# iostr912fa register map
Registers are 32-bit, access not given, no defined reset value unless marked. A register's access mark holds for its fields unless they carry their own. Addresses are absolute; registers are grouped by the start of their names; [hi:lo] are bit positions; {n}, {i} and the like mark numbered series; 'fields as' and 'values as' point back to an identical list.

## I2C0
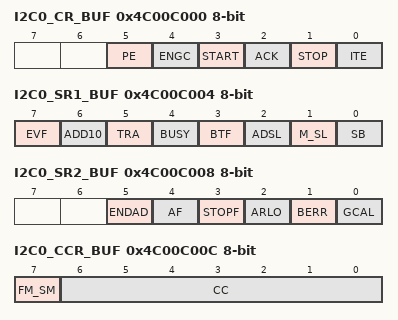
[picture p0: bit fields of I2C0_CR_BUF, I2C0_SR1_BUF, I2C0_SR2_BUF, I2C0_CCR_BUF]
0x4C00C000 I2C0_CR_BUF 8-bit
  [5] PE, [4] ENGC, [3] START, [2] ACK, [1] STOP, [0] ITE
0x4C00C004 I2C0_SR1_BUF 8-bit
  [7] EVF, [6] ADD10, [5] TRA, [4] BUSY, [3] BTF, [2] ADSL, [1] M_SL, [0] SB
0x4C00C008 I2C0_SR2_BUF 8-bit
  [5] ENDAD, [4] AF, [3] STOPF, [2] ARLO, [1] BERR, [0] GCAL
0x4C00C00C I2C0_CCR_BUF 8-bit
  [7] FM_SM, [6:0] CC
0x4C00C010 I2C0_OAR1_BUF 8-bit
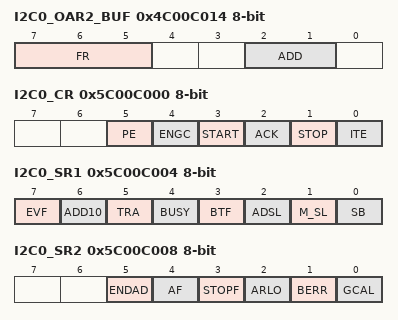
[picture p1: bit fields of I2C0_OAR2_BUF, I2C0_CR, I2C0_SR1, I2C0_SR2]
0x4C00C014 I2C0_OAR2_BUF 8-bit
  [7:5] FR, [2:1] ADD
0x4C00C018 I2C0_DR_BUF 8-bit
0x4C00C01C I2C0_ECCR_BUF 8-bit
  [4:0] CC
0x5C00C000 I2C0_CR 8-bit
  [5] PE, [4] ENGC, [3] START, [2] ACK, [1] STOP, [0] ITE
0x5C00C004 I2C0_SR1 8-bit
  fields as I2C0_SR1_BUF
0x5C00C008 I2C0_SR2 8-bit
  [5] ENDAD, [4] AF, [3] STOPF, [2] ARLO, [1] BERR, [0] GCAL
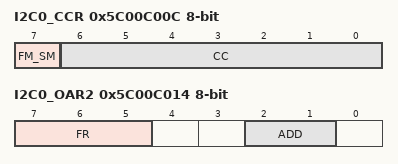
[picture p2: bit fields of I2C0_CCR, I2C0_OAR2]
0x5C00C00C I2C0_CCR 8-bit
  [7] FM_SM, [6:0] CC
0x5C00C010 I2C0_OAR1 8-bit
0x5C00C014 I2C0_OAR2 8-bit
  [7:5] FR, [2:1] ADD
0x5C00C018 I2C0_DR 8-bit
0x5C00C01C I2C0_ECCR 8-bit
  [4:0] CC

## I2C1
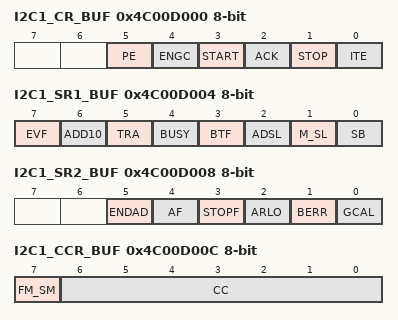
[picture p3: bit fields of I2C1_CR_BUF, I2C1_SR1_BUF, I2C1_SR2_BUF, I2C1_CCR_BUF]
0x4C00D000 I2C1_CR_BUF 8-bit
  [5] PE, [4] ENGC, [3] START, [2] ACK, [1] STOP, [0] ITE
0x4C00D004 I2C1_SR1_BUF 8-bit
  [7] EVF, [6] ADD10, [5] TRA, [4] BUSY, [3] BTF, [2] ADSL, [1] M_SL, [0] SB
0x4C00D008 I2C1_SR2_BUF 8-bit
  [5] ENDAD, [4] AF, [3] STOPF, [2] ARLO, [1] BERR, [0] GCAL
0x4C00D00C I2C1_CCR_BUF 8-bit
  [7] FM_SM, [6:0] CC
0x4C00D010 I2C1_OAR1_BUF 8-bit
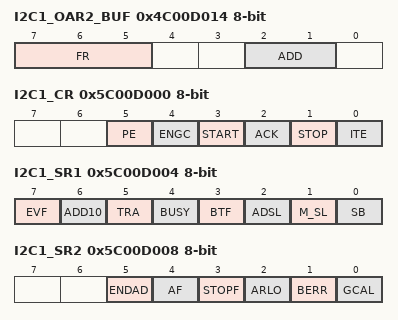
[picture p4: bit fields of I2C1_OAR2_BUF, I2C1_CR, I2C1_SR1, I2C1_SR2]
0x4C00D014 I2C1_OAR2_BUF 8-bit
  [7:5] FR, [2:1] ADD
0x4C00D018 I2C1_DR_BUF 8-bit
0x4C00D01C I2C1_ECCR_BUF 8-bit
  [4:0] CC
0x5C00D000 I2C1_CR 8-bit
  [5] PE, [4] ENGC, [3] START, [2] ACK, [1] STOP, [0] ITE
0x5C00D004 I2C1_SR1 8-bit
  fields as I2C1_SR1_BUF
0x5C00D008 I2C1_SR2 8-bit
  [5] ENDAD, [4] AF, [3] STOPF, [2] ARLO, [1] BERR, [0] GCAL
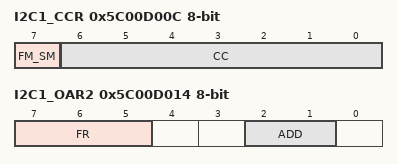
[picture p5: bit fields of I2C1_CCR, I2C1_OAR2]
0x5C00D00C I2C1_CCR 8-bit
  [7] FM_SM, [6:0] CC
0x5C00D010 I2C1_OAR1 8-bit
0x5C00D014 I2C1_OAR2 8-bit
  [7:5] FR, [2:1] ADD
0x5C00D018 I2C1_DR 8-bit
0x5C00D01C I2C1_ECCR 8-bit
  [4:0] CC

## MC
0x4C003000 MC_TCPT_BUF 16-bit
0x4C003004 MC_TCMP_BUF 8-bit
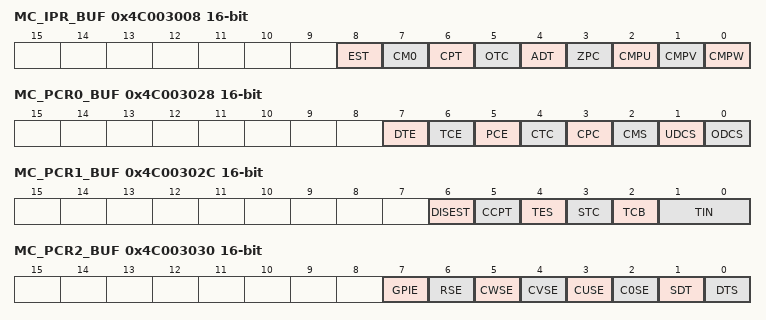
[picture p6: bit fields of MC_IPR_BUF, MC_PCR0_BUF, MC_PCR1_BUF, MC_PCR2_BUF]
0x4C003008 MC_IPR_BUF 16-bit
  [8] EST, [7] CM0, [6] CPT, [5] OTC, [4] ADT, [3] ZPC, [2] CMPU, [1] CMPV, [0] CMPW
0x4C00300C MC_TPRS_BUF 16-bit
  [11:0] TPRS
0x4C003010 MC_CPRS_BUF 8-bit
0x4C003014 MC_REP_BUF 8-bit
0x4C003018 MC_CMPW_BUF 16-bit
0x4C00301C MC_CMPV_BUF 16-bit
0x4C003020 MC_CMPU_BUF 16-bit
0x4C003024 MC_CMP0_BUF 16-bit
0x4C003028 MC_PCR0_BUF 16-bit
  [7] DTE, [6] TCE, [5] PCE, [4] CTC, [3] CPC, [2] CMS, [1] UDCS, [0] ODCS
0x4C00302C MC_PCR1_BUF 16-bit
  [6] DISEST, [5] CCPT, [4] TES, [3] STC, [2] TCB, [1:0] TIN
0x4C003030 MC_PCR2_BUF 16-bit
  [7] GPIE, [6] RSE, [5] CWSE, [4] CVSE, [3] CUSE, [2] C0SE, [1] SDT, [0] DTS
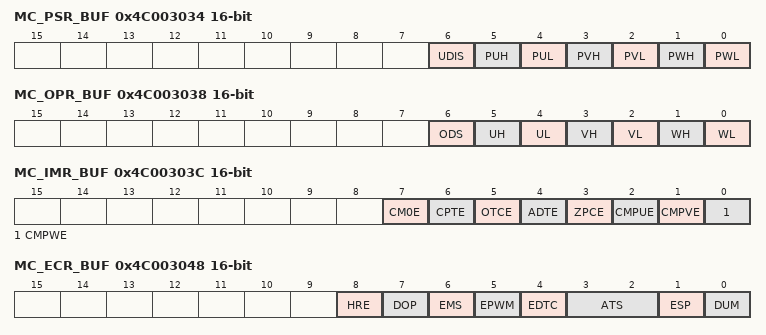
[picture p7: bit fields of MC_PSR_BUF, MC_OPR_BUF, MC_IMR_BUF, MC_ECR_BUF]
0x4C003034 MC_PSR_BUF 16-bit
  [6] UDIS, [5] PUH, [4] PUL, [3] PVH, [2] PVL, [1] PWH, [0] PWL
0x4C003038 MC_OPR_BUF 16-bit
  [6] ODS, [5] UH, [4] UL, [3] VH, [2] VL, [1] WH, [0] WL
0x4C00303C MC_IMR_BUF 16-bit
  [7] CM0E, [6] CPTE, [5] OTCE, [4] ADTE, [3] ZPCE, [2] CMPUE, [1] CMPVE, [0] CMPWE
0x4C003040 MC_DTG_BUF 16-bit
  [9:0] DTG
0x4C003044 MC_ESC_BUF 16-bit
0x4C003048 MC_ECR_BUF 16-bit
  [8] HRE, [7] DOP, [6] EMS, [5] EPWM, [4] EDTC, [3:2] ATS, [1] ESP, [0] DUM
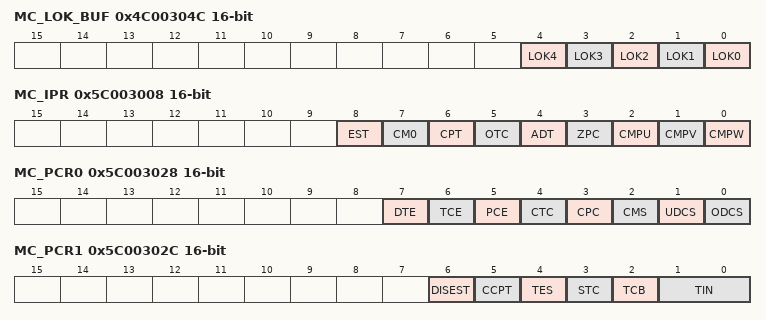
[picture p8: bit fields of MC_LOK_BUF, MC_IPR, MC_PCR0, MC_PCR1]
0x4C00304C MC_LOK_BUF 16-bit
  [n] LOK{n} (n=0..4)
0x5C003000 MC_TCPT 16-bit
0x5C003004 MC_TCMP 8-bit
0x5C003008 MC_IPR 16-bit
  fields as MC_IPR_BUF
0x5C00300C MC_TPRS 16-bit
  [11:0] TPRS
0x5C003010 MC_CPRS 8-bit
0x5C003014 MC_REP 8-bit
0x5C003018 MC_CMPW 16-bit
0x5C00301C MC_CMPV 16-bit
0x5C003020 MC_CMPU 16-bit
0x5C003024 MC_CMP0 16-bit
0x5C003028 MC_PCR0 16-bit
  fields as MC_PCR0_BUF
0x5C00302C MC_PCR1 16-bit
  [6] DISEST, [5] CCPT, [4] TES, [3] STC, [2] TCB, [1:0] TIN
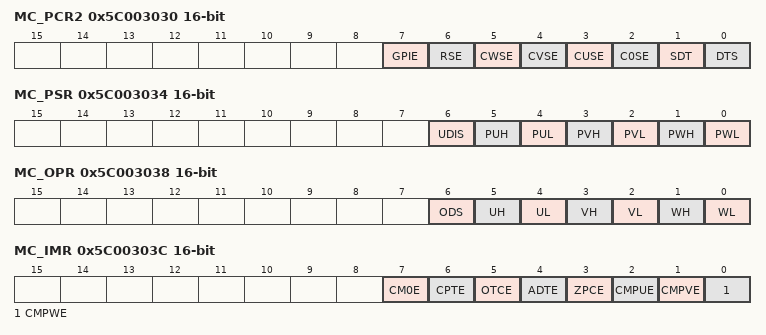
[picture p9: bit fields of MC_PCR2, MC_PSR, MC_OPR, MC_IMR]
0x5C003030 MC_PCR2 16-bit
  fields as MC_PCR2_BUF
0x5C003034 MC_PSR 16-bit
  [6] UDIS, [5] PUH, [4] PUL, [3] PVH, [2] PVL, [1] PWH, [0] PWL
0x5C003038 MC_OPR 16-bit
  [6] ODS, [5] UH, [4] UL, [3] VH, [2] VL, [1] WH, [0] WL
0x5C00303C MC_IMR 16-bit
  fields as MC_IMR_BUF
0x5C003040 MC_DTG 16-bit
  [9:0] DTG
0x5C003044 MC_ESC 16-bit
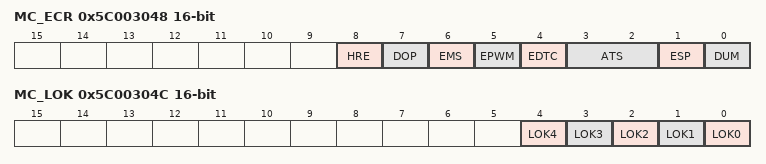
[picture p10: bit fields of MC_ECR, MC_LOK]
0x5C003048 MC_ECR 16-bit
  fields as MC_ECR_BUF
0x5C00304C MC_LOK 16-bit
  [n] LOK{n} (n=0..4)

## USB
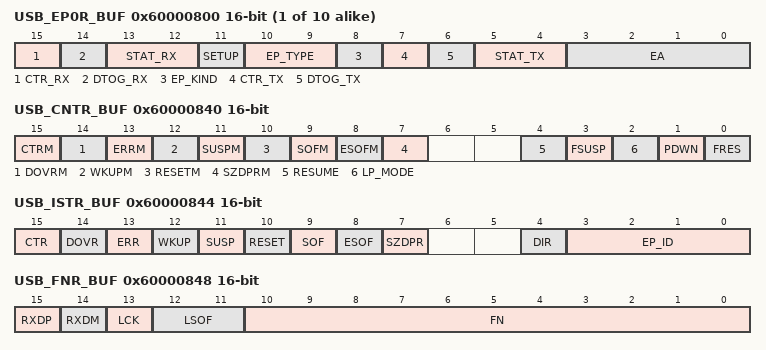
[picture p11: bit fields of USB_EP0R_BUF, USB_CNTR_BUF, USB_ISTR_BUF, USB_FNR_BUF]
{0x60000800+4i} USB_EP{i}R_BUF 16-bit (i=0..9)
  [15] CTR_RX, [14] DTOG_RX, [13:12] STAT_RX, [11] SETUP, [10:9] EP_TYPE, [8] EP_KIND, [7] CTR_TX, [6] DTOG_TX, [5:4] STAT_TX, [3:0] EA
0x60000840 USB_CNTR_BUF 16-bit
  [15] CTRM, [14] DOVRM, [13] ERRM, [12] WKUPM, [11] SUSPM, [10] RESETM, [9] SOFM, [8] ESOFM, [7] SZDPRM, [4] RESUME, [3] FSUSP, [2] LP_MODE, [1] PDWN, [0] FRES
0x60000844 USB_ISTR_BUF 16-bit
  [15] CTR, [14] DOVR, [13] ERR, [12] WKUP, [11] SUSP, [10] RESET, [9] SOF, [8] ESOF, [7] SZDPR, [4] DIR, [3:0] EP_ID
0x60000848 USB_FNR_BUF 16-bit
  [15] RXDP, [14] RXDM, [13] LCK, [12:11] LSOF, [10:0] FN
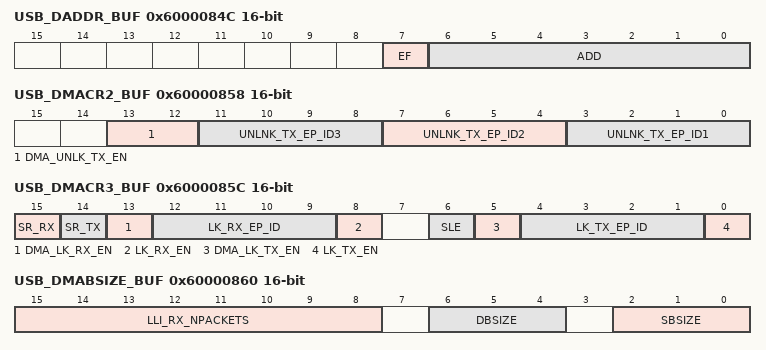
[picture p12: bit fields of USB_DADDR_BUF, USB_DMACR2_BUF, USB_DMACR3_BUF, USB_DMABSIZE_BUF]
0x6000084C USB_DADDR_BUF 16-bit
  [7] EF, [6:0] ADD
0x60000850 USB_BTABLE_BUF 16-bit
0x60000854 USB_DMACR1_BUF 16-bit
  [9:0] DMA_UNLK_RK_EN
0x60000858 USB_DMACR2_BUF 16-bit
  [13:12] DMA_UNLK_TX_EN, [11:8] UNLNK_TX_EP_ID3, [7:4] UNLNK_TX_EP_ID2, [3:0] UNLNK_TX_EP_ID1
0x6000085C USB_DMACR3_BUF 16-bit
  [15] SR_RX, [14] SR_TX, [13] DMA_LK_RX_EN, [12:9] LK_RX_EP_ID, [8] LK_RX_EN, [6] SLE, [5] DMA_LK_TX_EN, [4:1] LK_TX_EP_ID, [0] LK_TX_EN
0x60000860 USB_DMABSIZE_BUF 16-bit
  [15:8] LLI_RX_NPACKETS, [6:4] DBSIZE, [2:0] SBSIZE
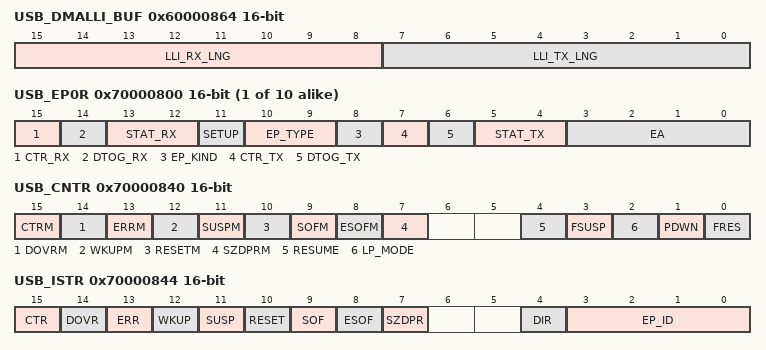
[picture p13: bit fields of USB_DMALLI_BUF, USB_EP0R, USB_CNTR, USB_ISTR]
0x60000864 USB_DMALLI_BUF 16-bit
  [15:8] LLI_RX_LNG, [7:0] LLI_TX_LNG
{0x70000800+4i} USB_EP{i}R 16-bit (i=0..9)
  fields as USB_EP0R_BUF
0x70000840 USB_CNTR 16-bit
  fields as USB_CNTR_BUF
0x70000844 USB_ISTR 16-bit
  fields as USB_ISTR_BUF
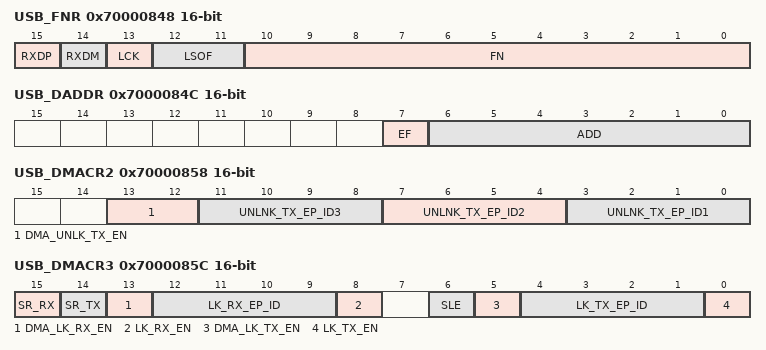
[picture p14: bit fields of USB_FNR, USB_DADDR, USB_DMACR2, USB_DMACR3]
0x70000848 USB_FNR 16-bit
  [15] RXDP, [14] RXDM, [13] LCK, [12:11] LSOF, [10:0] FN
0x7000084C USB_DADDR 16-bit
  [7] EF, [6:0] ADD
0x70000850 USB_BTABLE 16-bit
0x70000854 USB_DMACR1 16-bit
  [9:0] DMA_UNLK_RK_EN
0x70000858 USB_DMACR2 16-bit
  fields as USB_DMACR2_BUF
0x7000085C USB_DMACR3 16-bit
  fields as USB_DMACR3_BUF
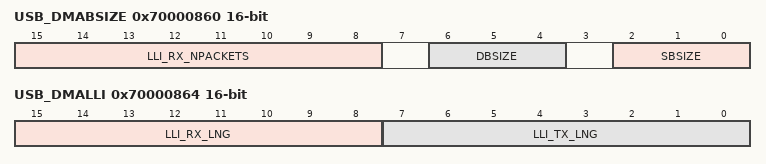
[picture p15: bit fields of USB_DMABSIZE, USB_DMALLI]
0x70000860 USB_DMABSIZE 16-bit
  [15:8] LLI_RX_NPACKETS, [6:4] DBSIZE, [2:0] SBSIZE
0x70000864 USB_DMALLI 16-bit
  [15:8] LLI_RX_LNG, [7:0] LLI_TX_LNG

## ADC
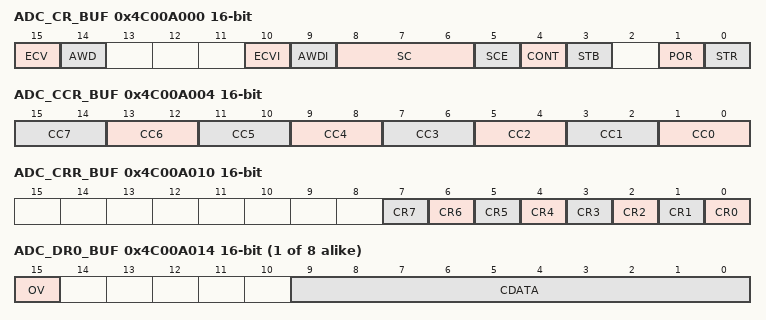
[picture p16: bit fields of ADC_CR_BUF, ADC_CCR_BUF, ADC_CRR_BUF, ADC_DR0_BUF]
0x4C00A000 ADC_CR_BUF 16-bit
  [15] ECV, [14] AWD, [10] ECVI, [9] AWDI, [8:6] SC, [5] SCE, [4] CONT, [3] STB, [1] POR, [0] STR
0x4C00A004 ADC_CCR_BUF 16-bit
  [2n+1:2n] CC{n} (n=0..7)
0x4C00A008 ADC_HTR_BUF 16-bit
  [9:0] HT
0x4C00A00C ADC_LTR_BUF 16-bit
  [9:0] LT
0x4C00A010 ADC_CRR_BUF 16-bit
  [n] CR{n} (n=0..7)
{0x4C00A014+4i} ADC_DR{i}_BUF 16-bit (i=0..7)
  [15] OV, [9:0] CDATA
0x4C00A034 ADC_PRS_BUF 8-bit
0x4C00A038 ADC_DDR_BUF 16-bit
  [15] OV, [13] OR, [12:10] CHANNELID, [9:0] CDATA
0x4C00A03C ADC_CR2_BUF 16-bit
  [5] ETE, [4] ORD, [3] DMAEN, [2] EXTRG, [1:0] TRIGSEL
0x5C00A000 ADC_CR 16-bit
  fields as ADC_CR_BUF
0x5C00A004 ADC_CCR 16-bit
  [2n+1:2n] CC{n} (n=0..7)
0x5C00A008 ADC_HTR 16-bit
  [9:0] HT
0x5C00A00C ADC_LTR 16-bit
  [9:0] LT
0x5C00A010 ADC_CRR 16-bit
  [n] CR{n} (n=0..7)
{0x5C00A014+4i} ADC_DR{i} 16-bit (i=0..7)
  [15] OV, [9:0] CDATA
0x5C00A034 ADC_PRS 8-bit
0x5C00A038 ADC_DDR 16-bit
  [15] OV, [13] OR, [12:10] CHANNELID, [9:0] CDATA
0x5C00A03C ADC_CR2 16-bit
  [5] ETE, [4] ORD, [3] DMAEN, [2] EXTRG, [1:0] TRIGSEL

## APB
0x48000000 APB_BSR_BUF
  [5] APBT, [4] OUTM, [0] ERROR
0x48000004 APB_BCR_BUF
  [24] SPLITEN, [20:16] SPLIT_CNT, [8] ERREN, [4:0] TOUT_CNT
0x48000008 APB_PAER_BUF
  [24] RW, [23:0] PERIPHERAL_ADDRESS
0x58000000 APB_BSR
  [5] APBT, [4] OUTM, [0] ERROR
0x58000004 APB_BCR
  [24] SPLITEN, [20:16] SPLIT_CNT, [8] ERREN, [4:0] TOUT_CNT
0x58000008 APB_PAER
  [24] RW, [23:0] PERIPHERAL_ADDRESS
